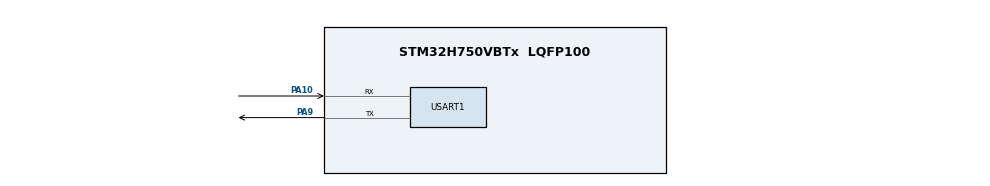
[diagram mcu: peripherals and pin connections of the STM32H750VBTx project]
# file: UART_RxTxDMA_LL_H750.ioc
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Dma.Request0=USART1_RX
Dma.Request1=USART1_TX
Dma.USART1_RX.0.Direction=DMA_PERIPH_TO_MEMORY
Dma.USART1_RX.0.EventEnable=DISABLE
Dma.USART1_RX.0.FIFOMode=DMA_FIFOMODE_DISABLE
Dma.USART1_RX.0.Instance=DMA1_Stream0
Dma.USART1_RX.0.MemDataAlignment=DMA_MDATAALIGN_BYTE
Dma.USART1_RX.0.MemInc=DMA_MINC_ENABLE
Dma.USART1_RX.0.Mode=DMA_NORMAL
Dma.USART1_RX.0.PeriphDataAlignment=DMA_PDATAALIGN_BYTE
Dma.USART1_RX.0.PeriphInc=DMA_PINC_DISABLE
Dma.USART1_RX.0.Polarity=HAL_DMAMUX_REQ_GEN_RISING
Dma.USART1_RX.0.Priority=DMA_PRIORITY_LOW
Dma.USART1_RX.0.RequestNumber=1
Dma.USART1_RX.0.SignalID=NONE
Dma.USART1_RX.0.SyncEnable=DISABLE
Dma.USART1_RX.0.SyncPolarity=HAL_DMAMUX_SYNC_NO_EVENT
Dma.USART1_RX.0.SyncRequestNumber=1
Dma.USART1_RX.0.SyncSignalID=NONE
Dma.USART1_TX.1.Direction=DMA_MEMORY_TO_PERIPH
Dma.USART1_TX.1.EventEnable=DISABLE
Dma.USART1_TX.1.FIFOMode=DMA_FIFOMODE_DISABLE
Dma.USART1_TX.1.Instance=DMA1_Stream1
Dma.USART1_TX.1.MemDataAlignment=DMA_MDATAALIGN_BYTE
Dma.USART1_TX.1.MemInc=DMA_MINC_ENABLE
Dma.USART1_TX.1.Mode=DMA_NORMAL
Dma.USART1_TX.1.PeriphDataAlignment=DMA_PDATAALIGN_BYTE
Dma.USART1_TX.1.PeriphInc=DMA_PINC_DISABLE
Dma.USART1_TX.1.Polarity=HAL_DMAMUX_REQ_GEN_RISING
Dma.USART1_TX.1.Priority=DMA_PRIORITY_LOW
Dma.USART1_TX.1.RequestNumber=1
Dma.USART1_TX.1.SignalID=NONE
Dma.USART1_TX.1.SyncEnable=DISABLE
Dma.USART1_TX.1.SyncPolarity=HAL_DMAMUX_SYNC_NO_EVENT
Dma.USART1_TX.1.SyncRequestNumber=1
Dma.USART1_TX.1.SyncSignalID=NONE
Mcu.Family=STM32H7
Mcu.Name=STM32H750VBTx
Mcu.Package=LQFP100
NVIC.DMA1_Stream0_IRQn=true\:0\:0\:false\:false\:true\:false\:true\:true
NVIC.DMA1_Stream1_IRQn=true\:0\:0\:false\:false\:true\:false\:true\:true
NVIC.PriorityGroup=NVIC_PRIORITYGROUP_4
PA10.Mode=Asynchronous
PA10.Signal=USART1_RX
PA13\ (JTMS/SWDIO).Mode=Serial_Wire
PA13\ (JTMS/SWDIO).Signal=DEBUG_JTMS-SWDIO
PA14\ (JTCK/SWCLK).Mode=Serial_Wire
PA14\ (JTCK/SWCLK).Signal=DEBUG_JTCK-SWCLK
PA9.Mode=Asynchronous
PA9.Signal=USART1_TX
PH0-OSC_IN\ (PH0).Mode=HSE-External-Oscillator
PH0-OSC_IN\ (PH0).Signal=RCC_OSC_IN
PH1-OSC_OUT\ (PH1).Mode=HSE-External-Oscillator
PH1-OSC_OUT\ (PH1).Signal=RCC_OSC_OUT
ProjectManager.HeapSize=0x200
ProjectManager.StackSize=0x400
ProjectManager.TargetToolchain=STM32CubeIDE
RCC.ADCFreq_Value=50390625
RCC.APB1Freq_Value=120000000
RCC.APB2Freq_Value=60000000
RCC.APB3Freq_Value=120000000
RCC.APB4Freq_Value=120000000
RCC.CortexFreq_Value=240000000
RCC.D2PPRE2=RCC_APB2_DIV2
RCC.DIVM1=25
RCC.DIVN1=480
RCC.HCLKFreq_Value=120000000
RCC.HPRE=RCC_HCLK_DIV2
RCC.PLLSourceVirtual=RCC_PLLSOURCE_HSE
RCC.SYSCLKFreq_VALUE=240000000
RCC.SYSCLKSource=RCC_SYSCLKSOURCE_PLLCLK
RCC.USBFreq_Value=240000000
USART1.VirtualMode-Asynchronous=VM_ASYNC
board=custom

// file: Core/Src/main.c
/* USER CODE BEGIN Header */
/**
  ******************************************************************************
  * @file           : main.c
  * @brief          : Main program body
  ******************************************************************************
  * @attention
  *
  * Copyright (c) 2023 STMicroelectronics.
  * All rights reserved.
  *
  * This software is licensed under terms that can be found in the LICENSE file
  * in the root directory of this software component.
  * If no LICENSE file comes with this software, it is provided AS-IS.
  *
  ******************************************************************************
  */
/* USER CODE END Header */
#include "main.h"

/* USER CODE BEGIN PV */
uint8_t buff[8];
/* USER CODE END PV */

void SystemClock_Config(void);
static void MX_GPIO_Init(void);
static void MX_DMA_Init(void);
static void MX_USART1_UART_Init(void);

int main(void)
{

  /* MCU Configuration--------------------------------------------------------*/

  /* Reset of all peripherals, Initializes the Flash interface and the Systick. */
  LL_APB4_GRP1_EnableClock(LL_APB4_GRP1_PERIPH_SYSCFG);

  /* System interrupt init*/
  NVIC_SetPriorityGrouping(NVIC_PRIORITYGROUP_4);

  /* SysTick_IRQn interrupt configuration */
  NVIC_SetPriority(SysTick_IRQn, NVIC_EncodePriority(NVIC_GetPriorityGrouping(),15, 0));

  /* Configure the system clock */
  SystemClock_Config();

  /* Initialize all configured peripherals */
  MX_GPIO_Init();
  MX_DMA_Init();
  MX_USART1_UART_Init();

  /* Infinite loop */
  /* USER CODE BEGIN WHILE */

  // 以下为RX处理
  LL_DMA_SetPeriphAddress(DMA1, LL_DMA_STREAM_0, LL_USART_DMA_GetRegAddr(USART1, LL_USART_DMA_REG_DATA_RECEIVE)); // 设置外设地址
  LL_DMA_EnableIT_TC(DMA1, LL_DMA_STREAM_0); // 启用传输完成中断
  LL_USART_EnableDMAReq_RX(USART1); // 使能串口接收发起DMA请求

  LL_DMA_SetMemoryAddress(DMA1, LL_DMA_STREAM_0, (uint32_t)buff); // 设备内存地址
  LL_DMA_SetDataLength(DMA1, LL_DMA_STREAM_0, sizeof(buff)/sizeof(uint8_t)); // 设置传输长度
  LL_DMA_EnableStream(DMA1, LL_DMA_STREAM_0); // 启动DMA传输

  // 以下TX处理
  LL_DMA_SetPeriphAddress(DMA1, LL_DMA_STREAM_1, LL_USART_DMA_GetRegAddr(USART1, LL_USART_DMA_REG_DATA_TRANSMIT)); // 设置外设地址
  LL_DMA_EnableIT_TC(DMA1, LL_DMA_STREAM_1); // 启用传输完成中断
  LL_USART_EnableDMAReq_TX(USART1); // 使能串口发送发起DMA请求

  while (1)
  {
    /* USER CODE END WHILE */

  }
}

void SystemClock_Config(void)
{
  LL_FLASH_SetLatency(LL_FLASH_LATENCY_2);
  while(LL_FLASH_GetLatency()!= LL_FLASH_LATENCY_2)
  {
  }
  LL_PWR_ConfigSupply(LL_PWR_LDO_SUPPLY);
  LL_PWR_SetRegulVoltageScaling(LL_PWR_REGU_VOLTAGE_SCALE2);
  while (LL_PWR_IsActiveFlag_VOS() == 0)
  {
  }
  LL_RCC_HSE_Enable();

   /* Wait till HSE is ready */
  while(LL_RCC_HSE_IsReady() != 1)
  {

  }
  LL_RCC_PLL_SetSource(LL_RCC_PLLSOURCE_HSE);
  LL_RCC_PLL1P_Enable();
  LL_RCC_PLL1R_Enable();
  LL_RCC_PLL1_SetVCOInputRange(LL_RCC_PLLINPUTRANGE_1_2);
  LL_RCC_PLL1_SetVCOOutputRange(LL_RCC_PLLVCORANGE_WIDE);
  LL_RCC_PLL1_SetM(25);
  LL_RCC_PLL1_SetN(480);
  LL_RCC_PLL1_SetP(2);
  LL_RCC_PLL1_SetQ(2);
  LL_RCC_PLL1_SetR(2);
  LL_RCC_PLL1_Enable();

   /* Wait till PLL is ready */
  while(LL_RCC_PLL1_IsReady() != 1)
  {
  }

   /* Intermediate AHB prescaler 2 when target frequency clock is higher than 80 MHz */
   LL_RCC_SetAHBPrescaler(LL_RCC_AHB_DIV_2);

  LL_RCC_SetSysClkSource(LL_RCC_SYS_CLKSOURCE_PLL1);

   /* Wait till System clock is ready */
  while(LL_RCC_GetSysClkSource() != LL_RCC_SYS_CLKSOURCE_STATUS_PLL1)
  {

  }
  LL_RCC_SetSysPrescaler(LL_RCC_SYSCLK_DIV_1);
  LL_RCC_SetAHBPrescaler(LL_RCC_AHB_DIV_2);
  LL_RCC_SetAPB1Prescaler(LL_RCC_APB1_DIV_1);
  LL_RCC_SetAPB2Prescaler(LL_RCC_APB2_DIV_2);
  LL_RCC_SetAPB3Prescaler(LL_RCC_APB3_DIV_1);
  LL_RCC_SetAPB4Prescaler(LL_RCC_APB4_DIV_1);

  LL_Init1msTick(240000000);

  LL_SetSystemCoreClock(240000000);
}

static void MX_USART1_UART_Init(void)
{

  LL_USART_InitTypeDef USART_InitStruct = {0};

  LL_GPIO_InitTypeDef GPIO_InitStruct = {0};

  LL_RCC_SetUSARTClockSource(LL_RCC_USART16_CLKSOURCE_PCLK2);

  /* Peripheral clock enable */
  LL_APB2_GRP1_EnableClock(LL_APB2_GRP1_PERIPH_USART1);

  LL_AHB4_GRP1_EnableClock(LL_AHB4_GRP1_PERIPH_GPIOA);
  /**USART1 GPIO Configuration
  PA9   ------> USART1_TX
  PA10   ------> USART1_RX
  */
  GPIO_InitStruct.Pin = LL_GPIO_PIN_9|LL_GPIO_PIN_10;
  GPIO_InitStruct.Mode = LL_GPIO_MODE_ALTERNATE;
  GPIO_InitStruct.Speed = LL_GPIO_SPEED_FREQ_LOW;
  GPIO_InitStruct.OutputType = LL_GPIO_OUTPUT_PUSHPULL;
  GPIO_InitStruct.Pull = LL_GPIO_PULL_NO;
  GPIO_InitStruct.Alternate = LL_GPIO_AF_7;
  LL_GPIO_Init(GPIOA, &GPIO_InitStruct);

  /* USART1 DMA Init */

  /* USART1_RX Init */
  LL_DMA_SetPeriphRequest(DMA1, LL_DMA_STREAM_0, LL_DMAMUX1_REQ_USART1_RX);

  LL_DMA_SetDataTransferDirection(DMA1, LL_DMA_STREAM_0, LL_DMA_DIRECTION_PERIPH_TO_MEMORY);

  LL_DMA_SetStreamPriorityLevel(DMA1, LL_DMA_STREAM_0, LL_DMA_PRIORITY_LOW);

  LL_DMA_SetMode(DMA1, LL_DMA_STREAM_0, LL_DMA_MODE_NORMAL);

  LL_DMA_SetPeriphIncMode(DMA1, LL_DMA_STREAM_0, LL_DMA_PERIPH_NOINCREMENT);

  LL_DMA_SetMemoryIncMode(DMA1, LL_DMA_STREAM_0, LL_DMA_MEMORY_INCREMENT);

  LL_DMA_SetPeriphSize(DMA1, LL_DMA_STREAM_0, LL_DMA_PDATAALIGN_BYTE);

  LL_DMA_SetMemorySize(DMA1, LL_DMA_STREAM_0, LL_DMA_MDATAALIGN_BYTE);

  LL_DMA_DisableFifoMode(DMA1, LL_DMA_STREAM_0);

  /* USART1_TX Init */
  LL_DMA_SetPeriphRequest(DMA1, LL_DMA_STREAM_1, LL_DMAMUX1_REQ_USART1_TX);

  LL_DMA_SetDataTransferDirection(DMA1, LL_DMA_STREAM_1, LL_DMA_DIRECTION_MEMORY_TO_PERIPH);

  LL_DMA_SetStreamPriorityLevel(DMA1, LL_DMA_STREAM_1, LL_DMA_PRIORITY_LOW);

  LL_DMA_SetMode(DMA1, LL_DMA_STREAM_1, LL_DMA_MODE_NORMAL);

  LL_DMA_SetPeriphIncMode(DMA1, LL_DMA_STREAM_1, LL_DMA_PERIPH_NOINCREMENT);

  LL_DMA_SetMemoryIncMode(DMA1, LL_DMA_STREAM_1, LL_DMA_MEMORY_INCREMENT);

  LL_DMA_SetPeriphSize(DMA1, LL_DMA_STREAM_1, LL_DMA_PDATAALIGN_BYTE);

  LL_DMA_SetMemorySize(DMA1, LL_DMA_STREAM_1, LL_DMA_MDATAALIGN_BYTE);

  LL_DMA_DisableFifoMode(DMA1, LL_DMA_STREAM_1);

  USART_InitStruct.PrescalerValue = LL_USART_PRESCALER_DIV1;
  USART_InitStruct.BaudRate = 115200;
  USART_InitStruct.DataWidth = LL_USART_DATAWIDTH_8B;
  USART_InitStruct.StopBits = LL_USART_STOPBITS_1;
  USART_InitStruct.Parity = LL_USART_PARITY_NONE;
  USART_InitStruct.TransferDirection = LL_USART_DIRECTION_TX_RX;
  USART_InitStruct.HardwareFlowControl = LL_USART_HWCONTROL_NONE;
  USART_InitStruct.OverSampling = LL_USART_OVERSAMPLING_16;
  LL_USART_Init(USART1, &USART_InitStruct);
  LL_USART_SetTXFIFOThreshold(USART1, LL_USART_FIFOTHRESHOLD_1_8);
  LL_USART_SetRXFIFOThreshold(USART1, LL_USART_FIFOTHRESHOLD_1_8);
  LL_USART_DisableFIFO(USART1);
  LL_USART_ConfigAsyncMode(USART1);

  LL_USART_Enable(USART1);

  /* Polling USART1 initialisation */
  while((!(LL_USART_IsActiveFlag_TEACK(USART1))) || (!(LL_USART_IsActiveFlag_REACK(USART1))))
  {
  }

}

static void MX_DMA_Init(void)
{

  /* Init with LL driver */
  /* DMA controller clock enable */
  LL_AHB1_GRP1_EnableClock(LL_AHB1_GRP1_PERIPH_DMA1);

  /* DMA interrupt init */
  /* DMA1_Stream0_IRQn interrupt configuration */
  NVIC_SetPriority(DMA1_Stream0_IRQn, NVIC_EncodePriority(NVIC_GetPriorityGrouping(),0, 0));
  NVIC_EnableIRQ(DMA1_Stream0_IRQn);
  /* DMA1_Stream1_IRQn interrupt configuration */
  NVIC_SetPriority(DMA1_Stream1_IRQn, NVIC_EncodePriority(NVIC_GetPriorityGrouping(),0, 0));
  NVIC_EnableIRQ(DMA1_Stream1_IRQn);

}

static void MX_GPIO_Init(void)
{

  /* GPIO Ports Clock Enable */
  LL_AHB4_GRP1_EnableClock(LL_AHB4_GRP1_PERIPH_GPIOH);
  LL_AHB4_GRP1_EnableClock(LL_AHB4_GRP1_PERIPH_GPIOA);

}

void Error_Handler(void)
{
  __disable_irq();
  while (1)
  {
  }
}
